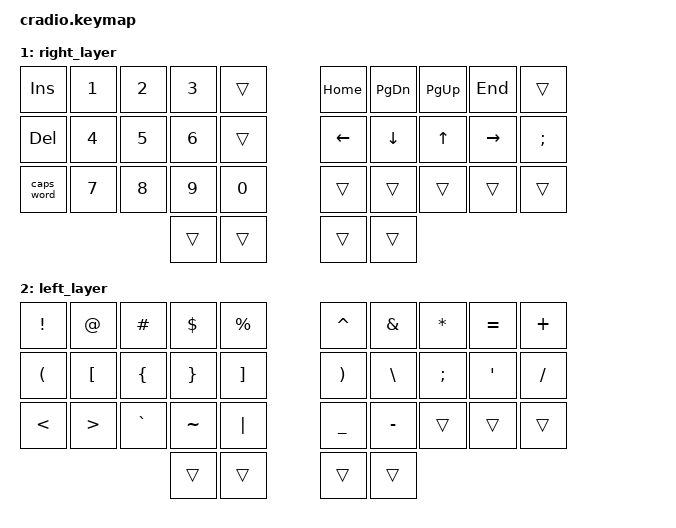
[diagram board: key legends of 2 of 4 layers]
// Copyright (c) 2022 The ZMK Contributors
// SPDX-License-Identifier: MIT

#include <behaviors.dtsi>
#include <dt-bindings/zmk/keys.h>
#include <dt-bindings/zmk/bt.h>

// Home row mods macro
#define HRML(k1,k2,k3,k4) &ht LSHFT k1  &ht LALT k2  &ht LCTRL k3  &ht LGUI k4
#define HRMR(k1,k2,k3,k4) &ht RGUI k1  &ht RCTRL k2  &ht RALT k3  &ht RSHFT k4

/ {
    behaviors {
        ht: hold_tap {
            compatible = "zmk,behavior-hold-tap";
            #binding-cells = <2>;
            flavor = "tap-preferred";
            tapping-term-ms = <220>;
            quick-tap-ms = <150>;
            require-prior-idle-ms = <100>;
            bindings = <&kp>, <&kp>;
        };

        bs_colon: backspace_colon {
            compatible = "zmk,behavior-hold-tap";
            #binding-cells = <2>;

            flavor = "tap-preferred";
            tapping-term-ms = <200>;
            quick-tap-ms = <150>;

            bindings = <&kp>, <&kp>;
        };
    };

    conditional_layers {
        compatible = "zmk,conditional-layers";

        tri_layer {
            if-layers = <1 2>;
            then-layer = <3>;
        };
    };
    keymap {
        compatible = "zmk,keymap";
        default_layer {
            bindings = <
        //╭──────────┬──────────┬──────────┬──────────┬──────────╮   ╭──────────┬──────────┬──────────┬──────────┬──────────╮
        //│  Q       │  W       │  F       │  P       │  G       │   │  J       │  L       │  U       │  Y       │  returns to alpha keys       │
            &kp Q      &kp W      &kp F      &kp P      &kp G          &kp J      &kp L      &kp U      &kp Y      &kp ESC
        //├──────────┼──────────┼──────────┼──────────┼──────────┤   ├──────────┼──────────┼──────────┼──────────┼──────────┤
        //│  A       │  R       │  S       │  T       │  D       │   │  H       │  N       │  E       │  I       │ O     │
            HRML(A,        R,         S,         T)     &kp D          &kp H      HRMR(N,        E,         I,        O)
        //├──────────┼──────────┼──────────┼──────────┼──────────┤   ├──────────┼──────────┼──────────┼──────────┼──────────┤
        //│  Z       │  X       │  C       │  V       │  B       │   │  K       │  M       │ , <      │ . >      │ / ?      │
            &kp Z      &kp X      &kp C      &kp V      &kp B          &kp K      &kp M      &kp COMMA  &kp DOT    &kp FSLH
        //╰──────────┴──────────┴──────────┼──────────┼──────────┤   ├──────────┼──────────┼──────────┴──────────┴──────────╯
                                            &kp TAB  &lt 2 ENTER     &lt 1 SPACE  &bs_colon COLON BSPC

        //                                 ╰──────────┴──────────╯   ╰──────────┴──────────╯
            >;
        };

        right_layer {
            bindings = <
        //╭──────────┬──────────┬──────────┬──────────┬──────────╮   ╭──────────┬──────────┬──────────┬──────────┬──────────╮
        //│ INSERT   │  1       │  2       │  3       │          │   │ HOME     │ PAGE DN  │ PAGE UP  │ END      │          │
            &kp INS    &kp N1     &kp N2     &kp N3     &trans         &kp HOME   &kp PG_DN  &kp PG_UP  &kp END    &trans
        //├──────────┼──────────┼──────────┼──────────┼──────────┤   ├──────────┼──────────┼──────────┼──────────┼──────────┤
        //│ DELETE   │  4       │  5       │  6       │          │   │ LEFT     │ DOWN     │ UP       │ RIGHT    │  ;       │
            &kp DEL    &kp N4     &kp N5     &kp N6     &trans         &kp LEFT   &kp DOWN   &kp UP   &kp RIGHT   &kp SEMI
        //├──────────┼──────────┼──────────┼──────────┼──────────┤   ├──────────┼──────────┼──────────┼──────────┼──────────┤
        //│ CAPS     │  7       │  8       │  9       │  0       │   │          │          │          │          │          │
           &caps_word  &kp N7     &kp N8     &kp N9     &kp N0         &trans     &trans     &trans     &trans     &trans
        //╰──────────┴──────────┴──────────┼──────────┼──────────┤   ├──────────┼──────────┼──────────┴──────────┴──────────╯
                                             &trans     &trans        &trans     &trans
        //                                 ╰──────────┴──────────╯   ╰──────────┴──────────╯
            >;
        };
  
left_layer {
    bindings = <
    //╭──────────┬──────────┬──────────┬──────────┬──────────╮   ╭──────────┬──────────┬──────────┬──────────┬──────────╮
    //│  !       │  @       │  #       │  $       │  %       │   │  ^       │  &       │  *       │  =       │  +       │
        &kp EXCL  &kp AT     &kp HASH   &kp DLLR   &kp PRCNT      &kp CARET &kp AMPS   &kp STAR   &kp EQUAL  &kp PLUS
    //├──────────┼──────────┼──────────┼──────────┼──────────┤   ├──────────┼──────────┼──────────┼──────────┼──────────┤
    //│  (       │  [       │  {       │  }       │  ]       │   │  )       │  \       │  ;       │  "       │  /       │
        &kp LPAR  &kp LBKT   &kp LBRC   &kp RBRC   &kp RBKT       &kp RPAR  &kp BSLH   &kp SEMI   &kp SQT  &kp FSLH
    //├──────────┼──────────┼──────────┼──────────┼──────────┤   ├──────────┼──────────┼──────────┼──────────┼──────────┤
    //│  <       │  >       │  `       │  ~       │  |       │   │  _       │  -       │         │         │         │
        &kp LT    &kp GT     &kp GRAVE  &kp TILDE  &kp PIPE       &kp UNDER &kp MINUS   &trans     &trans      &trans
    //╰──────────┴──────────┴──────────┼──────────┼──────────┤   ├──────────┼──────────┼──────────┴──────────┴──────────╯
                                         &trans     &trans         &trans     &trans
    //                                 ╰──────────┴──────────╯   ╰──────────┴──────────╯
    >;
};
      tri_layer {
            bindings = <
        //╭──────────┬──────────┬──────────┬──────────┬──────────╮   ╭──────────┬──────────┬──────────┬──────────┬──────────╮
        //│ │          │          │                   │PROFILE 0     │          │          │          │          │
           &trans  &trans     &trans     &trans        &bt BT_SEL 0   &trans    &kp C_BRI_UP&kp C_BRI_DN     &trans    &trans
        //├──────────┼──────────┼──────────┼──────────┼──────────┤   ├──────────┼──────────┼──────────┼──────────┼──────────┤
        //│BOOTLOADER│          │          │          │PROFILE 1 │   │          │          │          │          │BOOTLOADER│
          &bootloader &kp C_PREV &kp C_PP   &kp C_NEXT &bt BT_SEL 1    &kp C_VOL_UP  &kp C_VOL_DN     &kp C_MUTE  &bootloader
        //├──────────┼──────────┼──────────┼──────────┼──────────┤   ├──────────┼──────────┼──────────┼──────────┼──────────┤
        //│          │          │          │ CLEAR BT │PROFILE 2 │   │          │          │          │          │          │
            &sys_reset     &trans  &trans  &bt BT_CLR &bt BT_SEL 2    &trans     &trans     &trans     &trans     &sys_reset
        //╰──────────┴──────────┴──────────┼──────────┼──────────┤   ├──────────┼──────────┼──────────┴──────────┴──────────╯
                                             &trans     &trans         &trans     &trans
        //                                 ╰──────────┴──────────╯   ╰──────────┴──────────╯
            >;
        };
    };
};
